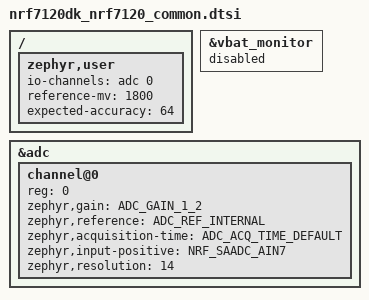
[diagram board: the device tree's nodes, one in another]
/*
 * Copyright (c) 2026 Nordic Semiconductor ASA
 *
 * SPDX-License-Identifier: Apache-2.0
 */

/ {
	zephyr,user {
		io-channels = <&adc 0>;
		reference-mv = <1800>;
		expected-accuracy = <64>;
	};
};

&vbat_monitor {
	status = "disabled";
};

&adc {
	#address-cells = <1>;
	#size-cells = <0>;
	status = "okay";

	/delete-node/ channel@0;

	channel@0 {
		reg = <0>;
		zephyr,gain = "ADC_GAIN_1_2";
		zephyr,reference = "ADC_REF_INTERNAL";
		zephyr,acquisition-time = <ADC_ACQ_TIME_DEFAULT>;
		zephyr,input-positive = <NRF_SAADC_AIN7>;
		zephyr,resolution = <14>;
	};
};
